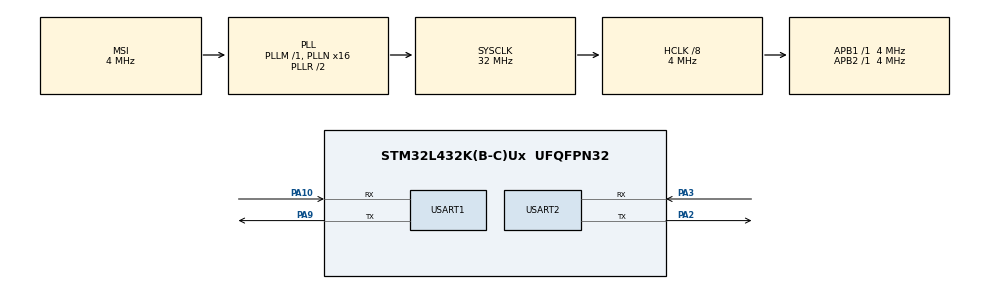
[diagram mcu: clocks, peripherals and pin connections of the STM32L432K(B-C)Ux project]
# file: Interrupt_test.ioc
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Mcu.Family=STM32L4
Mcu.Name=STM32L432K(B-C)Ux
Mcu.Package=UFQFPN32
NVIC.PriorityGroup=NVIC_PRIORITYGROUP_4
NVIC.USART1_IRQn=true\:0\:0\:false\:false\:true\:true\:true\:true
NVIC.USART2_IRQn=true\:0\:0\:false\:false\:true\:true\:true\:true
PA10.Mode=Asynchronous
PA10.Signal=USART1_RX
PA2.Mode=Asynchronous
PA2.Signal=USART2_TX
PA3.Mode=Asynchronous
PA3.Signal=USART2_RX
PA9.Mode=Asynchronous
PA9.Signal=USART1_TX
ProjectManager.HeapSize=0x200
ProjectManager.StackSize=0x400
ProjectManager.TargetToolchain=CMake
RCC.ADCFreq_Value=16000000
RCC.AHBCLKDivider=RCC_SYSCLK_DIV8
RCC.AHBFreq_Value=4000000
RCC.APB1Freq_Value=4000000
RCC.APB1TimFreq_Value=4000000
RCC.APB2Freq_Value=4000000
RCC.APB2TimFreq_Value=4000000
RCC.CortexFreq_Value=4000000
RCC.HCLKFreq_Value=4000000
RCC.HSE_VALUE=8000000
RCC.HSI48_VALUE=48000000
RCC.HSI_VALUE=16000000
RCC.LSE_VALUE=32768
RCC.MSI_VALUE=4000000
RCC.PLLN=16
RCC.SYSCLKFreq_VALUE=32000000
RCC.SYSCLKSource=RCC_SYSCLKSOURCE_PLLCLK
RCC.USBFreq_Value=16000000
RCC.VCOOutputFreq_Value=64000000
TIM16.Prescaler=31
USART1.VirtualMode-Asynchronous=VM_ASYNC
USART2.VirtualMode-Asynchronous=VM_ASYNC
VP_TIM16_VS_ClockSourceINT.Mode=Enable_Timer
board=custom

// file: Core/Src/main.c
/* USER CODE BEGIN Header */
/**
  ******************************************************************************
  * @file           : main.c
  * @brief          : Main program body
  ******************************************************************************
  * @attention
  *
  * Copyright (c) 2026 STMicroelectronics.
  * All rights reserved.
  *
  * This software is licensed under terms that can be found in the LICENSE file
  * in the root directory of this software component.
  * If no LICENSE file comes with this software, it is provided AS-IS.
  *
  ******************************************************************************
  */
/* USER CODE END Header */
#include "main.h"

TIM_HandleTypeDef htim16;

UART_HandleTypeDef huart1;
UART_HandleTypeDef huart2;

/* USER CODE BEGIN PV */
volatile uint8_t rx_byte = 0;
/* USER CODE END PV */

void SystemClock_Config(void);
static void MX_GPIO_Init(void);
static void MX_TIM16_Init(void);
static void MX_USART1_UART_Init(void);
static void MX_USART2_UART_Init(void);

/* USER CODE BEGIN 0 */
// This function runs automatically whenever a byte is received on USART2
void HAL_UART_RxCpltCallback(UART_HandleTypeDef *huart) {
    if (huart->Instance == USART2) {
        // Echo the byte back to the Mac immediately
        HAL_UART_Transmit(&huart2, (uint8_t *)&rx_byte, 1, 10);

        // Re-enable the interrupt to listen for the next character
        HAL_UART_Receive_IT(&huart2, (uint8_t *)&rx_byte, 1);
    }
}
/* USER CODE END 0 */

int main(void)
{

  /* MCU Configuration--------------------------------------------------------*/

  /* Reset of all peripherals, Initializes the Flash interface and the Systick. */
  HAL_Init();

  /* Configure the system clock */
  SystemClock_Config();

  /* Initialize all configured peripherals */
  MX_GPIO_Init();
  MX_TIM16_Init();
  MX_USART1_UART_Init();
  MX_USART2_UART_Init();
  /* USER CODE BEGIN 2 */
  // 1. Send a "Hello" message to confirm the TX line works
  uint8_t hello[] = "\r\nUART Echo Started. Type a character!\r\n";
  HAL_UART_Transmit(&huart2, hello, sizeof(hello)-1, 100);

  // 2. Clear any pending flags and start the first Interrupt listener
  __HAL_UART_CLEAR_FLAG(&huart2, UART_FLAG_ORE | UART_FLAG_NE | UART_FLAG_FE);
  HAL_UART_Receive_IT(&huart2, (uint8_t *)&rx_byte, 1);
  /* USER CODE END 2 */

  /* Infinite loop */
  while (1)
  {

  }
}

void SystemClock_Config(void)
{
  RCC_OscInitTypeDef RCC_OscInitStruct = {0};
  RCC_ClkInitTypeDef RCC_ClkInitStruct = {0};

  /** Configure the main internal regulator output voltage
  */
  if (HAL_PWREx_ControlVoltageScaling(PWR_REGULATOR_VOLTAGE_SCALE1) != HAL_OK)
  {
    Error_Handler();
  }

  /** Initializes the RCC Oscillators according to the specified parameters
  * in the RCC_OscInitTypeDef structure.
  */
  RCC_OscInitStruct.OscillatorType = RCC_OSCILLATORTYPE_MSI;
  RCC_OscInitStruct.MSIState = RCC_MSI_ON;
  RCC_OscInitStruct.MSICalibrationValue = 0;
  RCC_OscInitStruct.MSIClockRange = RCC_MSIRANGE_6;
  RCC_OscInitStruct.PLL.PLLState = RCC_PLL_ON;
  RCC_OscInitStruct.PLL.PLLSource = RCC_PLLSOURCE_MSI;
  RCC_OscInitStruct.PLL.PLLM = 1;
  RCC_OscInitStruct.PLL.PLLN = 16;
  RCC_OscInitStruct.PLL.PLLP = RCC_PLLP_DIV7;
  RCC_OscInitStruct.PLL.PLLQ = RCC_PLLQ_DIV2;
  RCC_OscInitStruct.PLL.PLLR = RCC_PLLR_DIV2;
  if (HAL_RCC_OscConfig(&RCC_OscInitStruct) != HAL_OK)
  {
    Error_Handler();
  }

  /** Initializes the CPU, AHB and APB buses clocks
  */
  RCC_ClkInitStruct.ClockType = RCC_CLOCKTYPE_HCLK|RCC_CLOCKTYPE_SYSCLK
                              |RCC_CLOCKTYPE_PCLK1|RCC_CLOCKTYPE_PCLK2;
  RCC_ClkInitStruct.SYSCLKSource = RCC_SYSCLKSOURCE_PLLCLK;
  RCC_ClkInitStruct.AHBCLKDivider = RCC_SYSCLK_DIV8;
  RCC_ClkInitStruct.APB1CLKDivider = RCC_HCLK_DIV1;
  RCC_ClkInitStruct.APB2CLKDivider = RCC_HCLK_DIV1;

  if (HAL_RCC_ClockConfig(&RCC_ClkInitStruct, FLASH_LATENCY_0) != HAL_OK)
  {
    Error_Handler();
  }
}

static void MX_TIM16_Init(void)
{

  htim16.Instance = TIM16;
  htim16.Init.Prescaler = 31;
  htim16.Init.CounterMode = TIM_COUNTERMODE_UP;
  htim16.Init.Period = 65535;
  htim16.Init.ClockDivision = TIM_CLOCKDIVISION_DIV1;
  htim16.Init.RepetitionCounter = 0;
  htim16.Init.AutoReloadPreload = TIM_AUTORELOAD_PRELOAD_DISABLE;
  if (HAL_TIM_Base_Init(&htim16) != HAL_OK)
  {
    Error_Handler();
  }

}

static void MX_USART1_UART_Init(void)
{

  huart1.Instance = USART1;
  huart1.Init.BaudRate = 115200;
  huart1.Init.WordLength = UART_WORDLENGTH_8B;
  huart1.Init.StopBits = UART_STOPBITS_1;
  huart1.Init.Parity = UART_PARITY_NONE;
  huart1.Init.Mode = UART_MODE_TX_RX;
  huart1.Init.HwFlowCtl = UART_HWCONTROL_NONE;
  huart1.Init.OverSampling = UART_OVERSAMPLING_16;
  huart1.Init.OneBitSampling = UART_ONE_BIT_SAMPLE_DISABLE;
  huart1.AdvancedInit.AdvFeatureInit = UART_ADVFEATURE_NO_INIT;
  if (HAL_UART_Init(&huart1) != HAL_OK)
  {
    Error_Handler();
  }

}

static void MX_USART2_UART_Init(void)
{

  huart2.Instance = USART2;
  huart2.Init.BaudRate = 115200;
  huart2.Init.WordLength = UART_WORDLENGTH_8B;
  huart2.Init.StopBits = UART_STOPBITS_1;
  huart2.Init.Parity = UART_PARITY_NONE;
  huart2.Init.Mode = UART_MODE_TX_RX;
  huart2.Init.HwFlowCtl = UART_HWCONTROL_NONE;
  huart2.Init.OverSampling = UART_OVERSAMPLING_16;
  huart2.Init.OneBitSampling = UART_ONE_BIT_SAMPLE_DISABLE;
  huart2.AdvancedInit.AdvFeatureInit = UART_ADVFEATURE_NO_INIT;
  if (HAL_UART_Init(&huart2) != HAL_OK)
  {
    Error_Handler();
  }

}

static void MX_GPIO_Init(void)
{

  /* GPIO Ports Clock Enable */
  __HAL_RCC_GPIOA_CLK_ENABLE();

}

void Error_Handler(void)
{
  __disable_irq();
  while (1)
  {
  }
}
